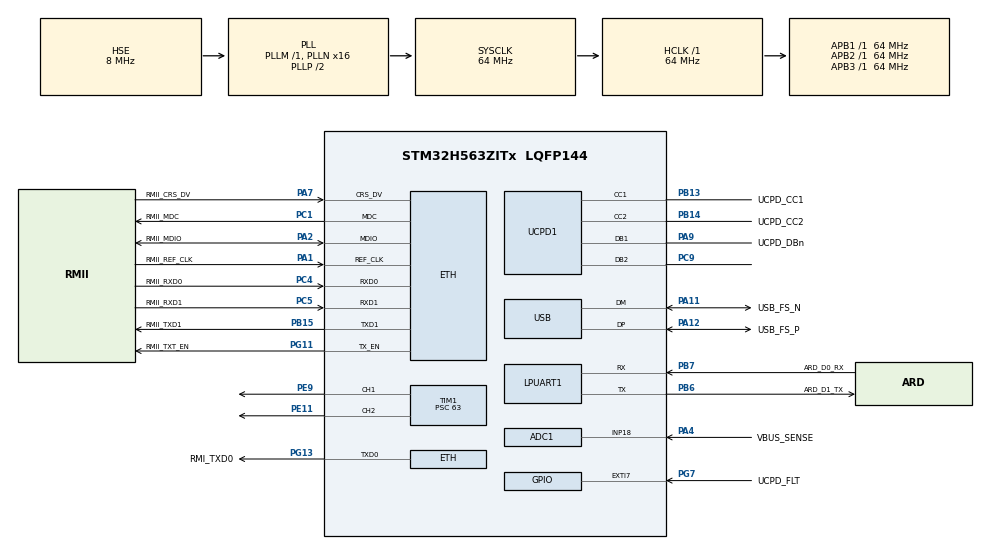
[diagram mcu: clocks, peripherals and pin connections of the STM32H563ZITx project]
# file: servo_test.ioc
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ADC1.Channel-0\#ChannelRegularConversion=ADC_CHANNEL_18
ADC1.MonitoredBy-0\#ChannelRegularConversion=__NULL
ADC1.NbrOfConversionFlag=1
ADC1.OffsetNumber-0\#ChannelRegularConversion=ADC_OFFSET_NONE
ADC1.Rank-0\#ChannelRegularConversion=1
ADC1.SamplingTime-0\#ChannelRegularConversion=ADC_SAMPLETIME_2CYCLES_5
ADC1.master=1
CORTEX_M33_NS.userName=CORTEX_M33
ETH.MediaInterface=HAL_ETH_RMII_MODE
Mcu.Family=STM32H5
Mcu.Name=STM32H563ZITx
Mcu.Package=LQFP144
NVIC.PriorityGroup=NVIC_PRIORITYGROUP_4
PA1.GPIO_Label=RMII_REF_CLK
PA1.GPIO_Mode=GPIO_MODE_AF_PP
PA1.GPIO_PuPd=GPIO_NOPULL
PA1.GPIO_Speed=GPIO_SPEED_FREQ_LOW
PA1.Mode=RMII
PA1.Signal=ETH_REF_CLK
PA11.GPIO_Label=USB_FS_N
PA11.Mode=Device
PA11.Signal=USB_DM
PA12.GPIO_Label=USB_FS_P
PA12.Mode=Device
PA12.Signal=USB_DP
PA13(JTMS/SWDIO).GPIO_Label=SWDIO
PA13(JTMS/SWDIO).Mode=Trace_Synchro_4bits_JTAG
PA13(JTMS/SWDIO).Signal=DEBUG_JTMS-SWDIO
PA14(JTCK/SWCLK).GPIO_Label=SWCLK
PA14(JTCK/SWCLK).Mode=Trace_Synchro_4bits_JTAG
PA14(JTCK/SWCLK).Signal=DEBUG_JTCK-SWCLK
PA15(JTDI).GPIO_Label=T_JTDI
PA15(JTDI).Mode=Trace_Synchro_4bits_JTAG
PA15(JTDI).Signal=DEBUG_JTDI
PA2.GPIO_Label=RMII_MDIO
PA2.GPIO_Mode=GPIO_MODE_AF_PP
PA2.GPIO_PuPd=GPIO_NOPULL
PA2.GPIO_Speed=GPIO_SPEED_FREQ_LOW
PA2.Mode=RMII
PA2.Signal=ETH_MDIO
PA4.GPIO_Label=VBUS_SENSE
PA4.Signal=ADCx_INP18
PA7.GPIO_Label=RMII_CRS_DV
PA7.GPIO_Mode=GPIO_MODE_AF_PP
PA7.GPIO_PuPd=GPIO_NOPULL
PA7.GPIO_Speed=GPIO_SPEED_FREQ_LOW
PA7.Mode=RMII
PA7.Signal=ETH_CRS_DV
PA9.GPIO_Label=UCPD_DBn
PA9.Mode=EnableDeadBattery
PA9.Signal=UCPD1_DB1
PB13.GPIO_Label=UCPD_CC1
PB13.Mode=Source_AllSignals
PB13.Signal=UCPD1_CC1
PB14.GPIO_Label=UCPD_CC2
PB14.Mode=Source_AllSignals
PB14.Signal=UCPD1_CC2
PB15.GPIO_Label=RMII_TXD1
PB15.GPIO_Mode=GPIO_MODE_AF_PP
PB15.GPIO_PuPd=GPIO_NOPULL
PB15.GPIO_Speed=GPIO_SPEED_FREQ_LOW
PB15.Mode=RMII
PB15.Signal=ETH_TXD1
PB3(JTDO/TRACESWO).GPIO_Label=SWO
PB3(JTDO/TRACESWO).Mode=Trace_Synchro_4bits_JTAG
PB3(JTDO/TRACESWO).Signal=DEBUG_JTDO-SWO
PB6.GPIO_Label=ARD_D1_TX
PB6.Mode=Asynchronous
PB6.Signal=LPUART1_TX
PB7.GPIO_Label=ARD_D0_RX
PB7.Mode=Asynchronous
PB7.Signal=LPUART1_RX
PC1.GPIO_Label=RMII_MDC
PC1.GPIO_Mode=GPIO_MODE_AF_PP
PC1.GPIO_PuPd=GPIO_NOPULL
PC1.GPIO_Speed=GPIO_SPEED_FREQ_LOW
PC1.Mode=RMII
PC1.Signal=ETH_MDC
PC14-OSC32_IN(OSC32_IN).Mode=LSE-External-Oscillator
PC14-OSC32_IN(OSC32_IN).Signal=RCC_OSC32_IN
PC15-OSC32_OUT(OSC32_OUT).Mode=LSE-External-Oscillator
PC15-OSC32_OUT(OSC32_OUT).Signal=RCC_OSC32_OUT
PC4.GPIO_Label=RMII_RXD0
PC4.GPIO_Mode=GPIO_MODE_AF_PP
PC4.GPIO_PuPd=GPIO_NOPULL
PC4.GPIO_Speed=GPIO_SPEED_FREQ_LOW
PC4.Mode=RMII
PC4.Signal=ETH_RXD0
PC5.GPIO_Label=RMII_RXD1
PC5.GPIO_Mode=GPIO_MODE_AF_PP
PC5.GPIO_PuPd=GPIO_NOPULL
PC5.GPIO_Speed=GPIO_SPEED_FREQ_LOW
PC5.Mode=RMII
PC5.Signal=ETH_RXD1
PC9.Mode=EnableDeadBattery
PC9.Signal=UCPD1_DB2
PE11.Signal=S_TIM1_CH2
PE2.GPIO_Label=TRACE_CK
PE2.Mode=Trace_Synchro_4bits_JTAG
PE2.Signal=DEBUG_TRACECLK
PE3.GPIO_Label=TRACE_D0
PE3.Mode=Trace_Synchro_4bits_JTAG
PE3.Signal=DEBUG_TRACED0
PE4.GPIO_Label=TRACE_D1
PE4.Mode=Trace_Synchro_4bits_JTAG
PE4.Signal=DEBUG_TRACED1
PE5.GPIO_Label=TRACE_D2
PE5.Mode=Trace_Synchro_4bits_JTAG
PE5.Signal=DEBUG_TRACED2
PE6.GPIO_Label=TRACE_D3
PE6.Mode=Trace_Synchro_4bits_JTAG
PE6.Signal=DEBUG_TRACED3
PE9.Signal=S_TIM1_CH1
PG11.GPIO_Label=RMII_TXT_EN
PG11.GPIO_Mode=GPIO_MODE_AF_PP
PG11.GPIO_PuPd=GPIO_NOPULL
PG11.GPIO_Speed=GPIO_SPEED_FREQ_LOW
PG11.Mode=RMII
PG11.Signal=ETH_TX_EN
PG13.GPIO_Label=RMI_TXD0
PG13.GPIO_Mode=GPIO_MODE_AF_PP
PG13.GPIO_PuPd=GPIO_NOPULL
PG13.GPIO_Speed=GPIO_SPEED_FREQ_LOW
PG13.Mode=RMII
PG13.Signal=ETH_TXD0
PG7.GPIO_Label=UCPD_FLT
PG7.Signal=GPXTI7
PH0-OSC_IN(PH0).Mode=HSE-DIG-External-Clock-Source
PH0-OSC_IN(PH0).Signal=RCC_OSC_IN
ProjectManager.HeapSize=0x200
ProjectManager.StackSize=0x400
ProjectManager.TargetToolchain=STM32CubeIDE
RCC.ADCFreq_Value=64000000
RCC.AHBFreq_Value=64000000
RCC.APB1Freq_Value=64000000
RCC.APB1TimFreq_Value=64000000
RCC.APB2Freq_Value=64000000
RCC.APB2TimFreq_Value=64000000
RCC.APB3Freq_Value=64000000
RCC.CSI_VALUE=4000000
RCC.CortexFreq_Value=64000000
RCC.EPOD_VALUE=8000000
RCC.HCLKFreq_Value=64000000
RCC.HSE_VALUE=8000000
RCC.HSI48_VALUE=48000000
RCC.HSIDiv=RCC_HSI_DIV1
RCC.HSI_VALUE=64000000
RCC.LSIRC_VALUE=32000
RCC.PLLFRACN=0
RCC.PLLN=16
RCC.PLLSourceVirtual=RCC_PLL1_SOURCE_HSE
RCC.SYSCLKFreq_VALUE=64000000
RCC.SYSCLKSource=RCC_SYSCLKSOURCE_PLLCLK
RCC.USBFreq_Value=48000000
RCC.VCOOutputFreq_Value=128000000
SH.ADCx_INP18.0=ADC1_INP18,IN18-Single-Ended
SH.S_TIM1_CH1.0=TIM1_CH1,PWM Generation1 CH1
SH.S_TIM1_CH2.0=TIM1_CH2,PWM Generation2 CH2
TIM1.Channel-PWM\ Generation1\ CH1=TIM_CHANNEL_1
TIM1.Channel-PWM\ Generation2\ CH2=TIM_CHANNEL_2
TIM1.PeriodNoDither=4096
TIM1.Prescaler=63
USB.VirtualMode=Device_Only
VP_BOOTPATH_VS_BOOTPATH.Mode=BP_Activate
VP_ICACHE_VS_ICACHE.Mode=DefaultMode
VP_MEMORYMAP_VS_MEMORYMAP.Mode=CurAppReg
VP_PWR_VS_DBSignals.Mode=DisableDeadBatterySignals
VP_PWR_VS_LPOM.Mode=PowerOptimisation
VP_PWR_VS_SECSignals.Mode=Security/Privilege
VP_TIM1_VS_ClockSourceINT.Mode=Internal
board=NUCLEO-H563ZI

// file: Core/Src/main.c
/* USER CODE BEGIN Header */
/**
  ******************************************************************************
  * @file           : main.c
  * @brief          : Main program body
  ******************************************************************************
  * @attention
  *
  * Copyright (c) 2024 STMicroelectronics.
  * All rights reserved.
  *
  * This software is licensed under terms that can be found in the LICENSE file
  * in the root directory of this software component.
  * If no LICENSE file comes with this software, it is provided AS-IS.
  *
  ******************************************************************************
  */
/* USER CODE END Header */
#include "main.h"
#include "string.h"

/* USER CODE BEGIN Includes */
#include "servo.h"
/* USER CODE END Includes */

ETH_TxPacketConfig TxConfig;
ETH_DMADescTypeDef  DMARxDscrTab[ETH_RX_DESC_CNT]; /* Ethernet Rx DMA Descriptors */
ETH_DMADescTypeDef  DMATxDscrTab[ETH_TX_DESC_CNT]; /* Ethernet Tx DMA Descriptors */

ADC_HandleTypeDef hadc1;

ETH_HandleTypeDef heth;

UART_HandleTypeDef hlpuart1;

TIM_HandleTypeDef htim1;

PCD_HandleTypeDef hpcd_USB_DRD_FS;

void SystemClock_Config(void);
static void MX_GPIO_Init(void);
static void MX_ADC1_Init(void);
static void MX_ETH_Init(void);
static void MX_ICACHE_Init(void);
static void MX_LPUART1_UART_Init(void);
static void MX_UCPD1_Init(void);
static void MX_USB_PCD_Init(void);
static void MX_TIM1_Init(void);

/* USER CODE BEGIN 0 */
uint16_t pwm1, pwm2, cycle=4096;
Servo servo1, servo2;
/* USER CODE END 0 */

int main(void)
{

  /* MCU Configuration--------------------------------------------------------*/

  /* Reset of all peripherals, Initializes the Flash interface and the Systick. */
  HAL_Init();

  /* Configure the system clock */
  SystemClock_Config();

  /* Initialize all configured peripherals */
  MX_GPIO_Init();
  MX_ADC1_Init();
  MX_ETH_Init();
  MX_ICACHE_Init();
  MX_LPUART1_UART_Init();
  MX_UCPD1_Init();
  MX_USB_PCD_Init();
  MX_TIM1_Init();
  /* USER CODE BEGIN 2 */
  SERVO_INIT(&htim1, cycle);
  Servo_Start(&servo1, TIM_CHANNEL_1);
  Servo_Start(&servo2, TIM_CHANNEL_2);
  /* USER CODE END 2 */

  /* Infinite loop */
  /* USER CODE BEGIN WHILE */
  while (1)
  {
	  Servo_Write(&servo1, pwm1);
	  Servo_Write(&servo2, pwm2);
    /* USER CODE END WHILE */

  }
}

void SystemClock_Config(void)
{
  RCC_OscInitTypeDef RCC_OscInitStruct = {0};
  RCC_ClkInitTypeDef RCC_ClkInitStruct = {0};

  /** Configure the main internal regulator output voltage
  */
  __HAL_PWR_VOLTAGESCALING_CONFIG(PWR_REGULATOR_VOLTAGE_SCALE3);

  while(!__HAL_PWR_GET_FLAG(PWR_FLAG_VOSRDY)) {}

  /** Initializes the RCC Oscillators according to the specified parameters
  * in the RCC_OscInitTypeDef structure.
  */
  RCC_OscInitStruct.OscillatorType = RCC_OSCILLATORTYPE_HSI48|RCC_OSCILLATORTYPE_HSI
                              |RCC_OSCILLATORTYPE_HSE;
  RCC_OscInitStruct.HSEState = RCC_HSE_BYPASS_DIGITAL;
  RCC_OscInitStruct.HSIState = RCC_HSI_ON;
  RCC_OscInitStruct.HSIDiv = RCC_HSI_DIV1;
  RCC_OscInitStruct.HSICalibrationValue = RCC_HSICALIBRATION_DEFAULT;
  RCC_OscInitStruct.HSI48State = RCC_HSI48_ON;
  RCC_OscInitStruct.PLL.PLLState = RCC_PLL_ON;
  RCC_OscInitStruct.PLL.PLLSource = RCC_PLL1_SOURCE_HSE;
  RCC_OscInitStruct.PLL.PLLM = 1;
  RCC_OscInitStruct.PLL.PLLN = 16;
  RCC_OscInitStruct.PLL.PLLP = 2;
  RCC_OscInitStruct.PLL.PLLQ = 2;
  RCC_OscInitStruct.PLL.PLLR = 2;
  RCC_OscInitStruct.PLL.PLLRGE = RCC_PLL1_VCIRANGE_3;
  RCC_OscInitStruct.PLL.PLLVCOSEL = RCC_PLL1_VCORANGE_WIDE;
  RCC_OscInitStruct.PLL.PLLFRACN = 0;
  if (HAL_RCC_OscConfig(&RCC_OscInitStruct) != HAL_OK)
  {
    Error_Handler();
  }

  /** Initializes the CPU, AHB and APB buses clocks
  */
  RCC_ClkInitStruct.ClockType = RCC_CLOCKTYPE_HCLK|RCC_CLOCKTYPE_SYSCLK
                              |RCC_CLOCKTYPE_PCLK1|RCC_CLOCKTYPE_PCLK2
                              |RCC_CLOCKTYPE_PCLK3;
  RCC_ClkInitStruct.SYSCLKSource = RCC_SYSCLKSOURCE_PLLCLK;
  RCC_ClkInitStruct.AHBCLKDivider = RCC_SYSCLK_DIV1;
  RCC_ClkInitStruct.APB1CLKDivider = RCC_HCLK_DIV1;
  RCC_ClkInitStruct.APB2CLKDivider = RCC_HCLK_DIV1;
  RCC_ClkInitStruct.APB3CLKDivider = RCC_HCLK_DIV1;

  if (HAL_RCC_ClockConfig(&RCC_ClkInitStruct, FLASH_LATENCY_3) != HAL_OK)
  {
    Error_Handler();
  }
}

static void MX_ADC1_Init(void)
{

  ADC_ChannelConfTypeDef sConfig = {0};

  /** Common config
  */
  hadc1.Instance = ADC1;
  hadc1.Init.ClockPrescaler = ADC_CLOCK_ASYNC_DIV1;
  hadc1.Init.Resolution = ADC_RESOLUTION_12B;
  hadc1.Init.DataAlign = ADC_DATAALIGN_RIGHT;
  hadc1.Init.ScanConvMode = ADC_SCAN_DISABLE;
  hadc1.Init.EOCSelection = ADC_EOC_SINGLE_CONV;
  hadc1.Init.LowPowerAutoWait = DISABLE;
  hadc1.Init.ContinuousConvMode = DISABLE;
  hadc1.Init.NbrOfConversion = 1;
  hadc1.Init.DiscontinuousConvMode = DISABLE;
  hadc1.Init.ExternalTrigConv = ADC_SOFTWARE_START;
  hadc1.Init.ExternalTrigConvEdge = ADC_EXTERNALTRIGCONVEDGE_NONE;
  hadc1.Init.DMAContinuousRequests = DISABLE;
  hadc1.Init.SamplingMode = ADC_SAMPLING_MODE_NORMAL;
  hadc1.Init.Overrun = ADC_OVR_DATA_PRESERVED;
  hadc1.Init.OversamplingMode = DISABLE;
  if (HAL_ADC_Init(&hadc1) != HAL_OK)
  {
    Error_Handler();
  }

  /** Configure Regular Channel
  */
  sConfig.Channel = ADC_CHANNEL_18;
  sConfig.Rank = ADC_REGULAR_RANK_1;
  sConfig.SamplingTime = ADC_SAMPLETIME_2CYCLES_5;
  sConfig.SingleDiff = ADC_SINGLE_ENDED;
  sConfig.OffsetNumber = ADC_OFFSET_NONE;
  sConfig.Offset = 0;
  if (HAL_ADC_ConfigChannel(&hadc1, &sConfig) != HAL_OK)
  {
    Error_Handler();
  }

}

static void MX_ETH_Init(void)
{

   static uint8_t MACAddr[6];

  heth.Instance = ETH;
  MACAddr[0] = 0x00;
  MACAddr[1] = 0x80;
  MACAddr[2] = 0xE1;
  MACAddr[3] = 0x00;
  MACAddr[4] = 0x00;
  MACAddr[5] = 0x00;
  heth.Init.MACAddr = &MACAddr[0];
  heth.Init.MediaInterface = HAL_ETH_RMII_MODE;
  heth.Init.TxDesc = DMATxDscrTab;
  heth.Init.RxDesc = DMARxDscrTab;
  heth.Init.RxBuffLen = 1524;

  if (HAL_ETH_Init(&heth) != HAL_OK)
  {
    Error_Handler();
  }

  memset(&TxConfig, 0 , sizeof(ETH_TxPacketConfig));
  TxConfig.Attributes = ETH_TX_PACKETS_FEATURES_CSUM | ETH_TX_PACKETS_FEATURES_CRCPAD;
  TxConfig.ChecksumCtrl = ETH_CHECKSUM_IPHDR_PAYLOAD_INSERT_PHDR_CALC;
  TxConfig.CRCPadCtrl = ETH_CRC_PAD_INSERT;

}

static void MX_ICACHE_Init(void)
{

  /** Enable instruction cache (default 2-ways set associative cache)
  */
  if (HAL_ICACHE_Enable() != HAL_OK)
  {
    Error_Handler();
  }

}

static void MX_LPUART1_UART_Init(void)
{

  hlpuart1.Instance = LPUART1;
  hlpuart1.Init.BaudRate = 209700;
  hlpuart1.Init.WordLength = UART_WORDLENGTH_8B;
  hlpuart1.Init.StopBits = UART_STOPBITS_1;
  hlpuart1.Init.Parity = UART_PARITY_NONE;
  hlpuart1.Init.Mode = UART_MODE_TX_RX;
  hlpuart1.Init.HwFlowCtl = UART_HWCONTROL_NONE;
  hlpuart1.Init.OneBitSampling = UART_ONE_BIT_SAMPLE_DISABLE;
  hlpuart1.AdvancedInit.AdvFeatureInit = UART_ADVFEATURE_NO_INIT;
  hlpuart1.FifoMode = UART_FIFOMODE_DISABLE;
  if (HAL_UART_Init(&hlpuart1) != HAL_OK)
  {
    Error_Handler();
  }
  if (HAL_UARTEx_SetTxFifoThreshold(&hlpuart1, UART_TXFIFO_THRESHOLD_1_8) != HAL_OK)
  {
    Error_Handler();
  }
  if (HAL_UARTEx_SetRxFifoThreshold(&hlpuart1, UART_RXFIFO_THRESHOLD_1_8) != HAL_OK)
  {
    Error_Handler();
  }
  if (HAL_UARTEx_DisableFifoMode(&hlpuart1) != HAL_OK)
  {
    Error_Handler();
  }

}

static void MX_TIM1_Init(void)
{

  TIM_ClockConfigTypeDef sClockSourceConfig = {0};
  TIM_MasterConfigTypeDef sMasterConfig = {0};
  TIM_OC_InitTypeDef sConfigOC = {0};
  TIM_BreakDeadTimeConfigTypeDef sBreakDeadTimeConfig = {0};

  htim1.Instance = TIM1;
  htim1.Init.Prescaler = 63;
  htim1.Init.CounterMode = TIM_COUNTERMODE_UP;
  htim1.Init.Period = 4096;
  htim1.Init.ClockDivision = TIM_CLOCKDIVISION_DIV1;
  htim1.Init.RepetitionCounter = 0;
  htim1.Init.AutoReloadPreload = TIM_AUTORELOAD_PRELOAD_DISABLE;
  if (HAL_TIM_Base_Init(&htim1) != HAL_OK)
  {
    Error_Handler();
  }
  sClockSourceConfig.ClockSource = TIM_CLOCKSOURCE_INTERNAL;
  if (HAL_TIM_ConfigClockSource(&htim1, &sClockSourceConfig) != HAL_OK)
  {
    Error_Handler();
  }
  if (HAL_TIM_PWM_Init(&htim1) != HAL_OK)
  {
    Error_Handler();
  }
  sMasterConfig.MasterOutputTrigger = TIM_TRGO_RESET;
  sMasterConfig.MasterOutputTrigger2 = TIM_TRGO2_RESET;
  sMasterConfig.MasterSlaveMode = TIM_MASTERSLAVEMODE_DISABLE;
  if (HAL_TIMEx_MasterConfigSynchronization(&htim1, &sMasterConfig) != HAL_OK)
  {
    Error_Handler();
  }
  sConfigOC.OCMode = TIM_OCMODE_PWM1;
  sConfigOC.Pulse = 0;
  sConfigOC.OCPolarity = TIM_OCPOLARITY_HIGH;
  sConfigOC.OCNPolarity = TIM_OCNPOLARITY_HIGH;
  sConfigOC.OCFastMode = TIM_OCFAST_DISABLE;
  sConfigOC.OCIdleState = TIM_OCIDLESTATE_RESET;
  sConfigOC.OCNIdleState = TIM_OCNIDLESTATE_RESET;
  if (HAL_TIM_PWM_ConfigChannel(&htim1, &sConfigOC, TIM_CHANNEL_1) != HAL_OK)
  {
    Error_Handler();
  }
  if (HAL_TIM_PWM_ConfigChannel(&htim1, &sConfigOC, TIM_CHANNEL_2) != HAL_OK)
  {
    Error_Handler();
  }
  sBreakDeadTimeConfig.OffStateRunMode = TIM_OSSR_DISABLE;
  sBreakDeadTimeConfig.OffStateIDLEMode = TIM_OSSI_DISABLE;
  sBreakDeadTimeConfig.LockLevel = TIM_LOCKLEVEL_OFF;
  sBreakDeadTimeConfig.DeadTime = 0;
  sBreakDeadTimeConfig.BreakState = TIM_BREAK_DISABLE;
  sBreakDeadTimeConfig.BreakPolarity = TIM_BREAKPOLARITY_HIGH;
  sBreakDeadTimeConfig.BreakFilter = 0;
  sBreakDeadTimeConfig.BreakAFMode = TIM_BREAK_AFMODE_INPUT;
  sBreakDeadTimeConfig.Break2State = TIM_BREAK2_DISABLE;
  sBreakDeadTimeConfig.Break2Polarity = TIM_BREAK2POLARITY_HIGH;
  sBreakDeadTimeConfig.Break2Filter = 0;
  sBreakDeadTimeConfig.Break2AFMode = TIM_BREAK_AFMODE_INPUT;
  sBreakDeadTimeConfig.AutomaticOutput = TIM_AUTOMATICOUTPUT_DISABLE;
  if (HAL_TIMEx_ConfigBreakDeadTime(&htim1, &sBreakDeadTimeConfig) != HAL_OK)
  {
    Error_Handler();
  }
  HAL_TIM_MspPostInit(&htim1);

}

static void MX_UCPD1_Init(void)
{

  LL_GPIO_InitTypeDef GPIO_InitStruct = {0};

  /* Peripheral clock enable */
  LL_APB1_GRP2_EnableClock(LL_APB1_GRP2_PERIPH_UCPD1);

  LL_AHB2_GRP1_EnableClock(LL_AHB2_GRP1_PERIPH_GPIOB);
  /**UCPD1 GPIO Configuration
  PB13   ------> UCPD1_CC1
  PB14   ------> UCPD1_CC2
  */
  GPIO_InitStruct.Pin = LL_GPIO_PIN_13|LL_GPIO_PIN_14;
  GPIO_InitStruct.Mode = LL_GPIO_MODE_ANALOG;
  GPIO_InitStruct.Pull = LL_GPIO_PULL_NO;
  LL_GPIO_Init(GPIOB, &GPIO_InitStruct);

}

static void MX_USB_PCD_Init(void)
{

  hpcd_USB_DRD_FS.Instance = USB_DRD_FS;
  hpcd_USB_DRD_FS.Init.dev_endpoints = 8;
  hpcd_USB_DRD_FS.Init.speed = USBD_FS_SPEED;
  hpcd_USB_DRD_FS.Init.phy_itface = PCD_PHY_EMBEDDED;
  hpcd_USB_DRD_FS.Init.Sof_enable = DISABLE;
  hpcd_USB_DRD_FS.Init.low_power_enable = DISABLE;
  hpcd_USB_DRD_FS.Init.lpm_enable = DISABLE;
  hpcd_USB_DRD_FS.Init.battery_charging_enable = DISABLE;
  hpcd_USB_DRD_FS.Init.vbus_sensing_enable = DISABLE;
  hpcd_USB_DRD_FS.Init.bulk_doublebuffer_enable = DISABLE;
  hpcd_USB_DRD_FS.Init.iso_singlebuffer_enable = DISABLE;
  if (HAL_PCD_Init(&hpcd_USB_DRD_FS) != HAL_OK)
  {
    Error_Handler();
  }

}

static void MX_GPIO_Init(void)
{
  GPIO_InitTypeDef GPIO_InitStruct = {0};

  /* GPIO Ports Clock Enable */
  __HAL_RCC_GPIOE_CLK_ENABLE();
  __HAL_RCC_GPIOC_CLK_ENABLE();
  __HAL_RCC_GPIOH_CLK_ENABLE();
  __HAL_RCC_GPIOA_CLK_ENABLE();
  __HAL_RCC_GPIOB_CLK_ENABLE();
  __HAL_RCC_GPIOG_CLK_ENABLE();

  /*Configure GPIO pin : UCPD_FLT_Pin */
  GPIO_InitStruct.Pin = UCPD_FLT_Pin;
  GPIO_InitStruct.Mode = GPIO_MODE_IT_RISING;
  GPIO_InitStruct.Pull = GPIO_NOPULL;
  HAL_GPIO_Init(UCPD_FLT_GPIO_Port, &GPIO_InitStruct);

}

void Error_Handler(void)
{
  __disable_irq();
  while (1)
  {
  }
}
